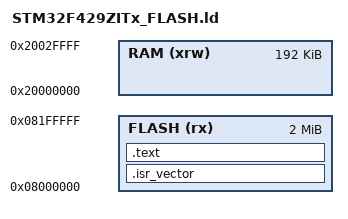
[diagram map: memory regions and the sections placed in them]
/* Entry Point */
ENTRY(Reset_Handler)

/* Specify the memory areas */
MEMORY
{
  RAM (xrw)      : ORIGIN = 0x20000000, LENGTH = 192K
  FLASH (rx)     : ORIGIN = 0x08000000, LENGTH = 2048K
}

/* Define output sections */
SECTIONS
{
  /* The startup code goes first into FLASH */
  .isr_vector :
  {
    . = ALIGN(4);
    KEEP(*(.isr_vector)) /* Startup code */
    . = ALIGN(4);
  } >FLASH

  /* The program code and other data goes into FLASH */
  .text :
  {
    . = ALIGN(4);
    *(.text)           /* .text sections (code) */
    *(.text*)          /* .text* sections (code) */
    . = ALIGN(4);
    _etext = .;        /* define a global symbols at end of code */
  } >FLASH

}


